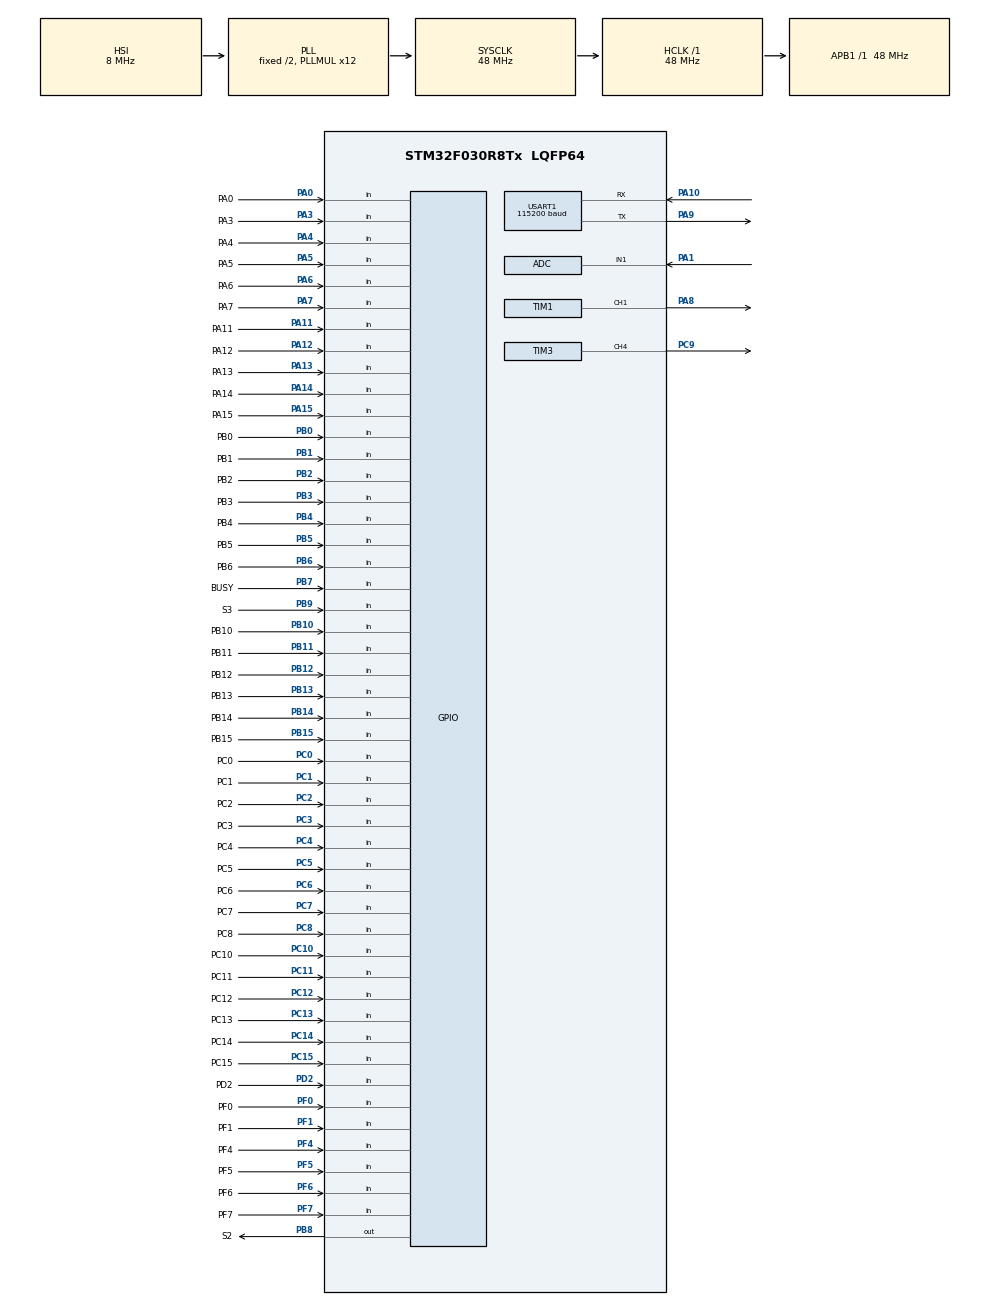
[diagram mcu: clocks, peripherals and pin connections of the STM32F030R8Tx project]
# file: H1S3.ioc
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Mcu.Family=STM32F0
Mcu.Name=STM32F030R8Tx
Mcu.Package=LQFP64
NVIC.USART1_IRQn=true\:0\:0\:false\:false\:true\:true\:true\:true
PA0.GPIO_Label=PA0
PA0.GPIO_PuPd=GPIO_PULLUP
PA0.Signal=GPIO_Input
PA1.Mode=IN1
PA1.Signal=ADC_IN1
PA10.Mode=Asynchronous
PA10.Signal=USART1_RX
PA11.GPIO_Label=PA11
PA11.GPIO_PuPd=GPIO_PULLUP
PA11.Signal=GPIO_Input
PA12.GPIO_Label=PA12
PA12.GPIO_PuPd=GPIO_PULLUP
PA12.Signal=GPIO_Input
PA13.GPIO_Label=PA13
PA13.GPIO_PuPd=GPIO_PULLUP
PA13.Signal=GPIO_Input
PA14.GPIO_Label=PA14
PA14.GPIO_PuPd=GPIO_PULLUP
PA14.Signal=GPIO_Input
PA15.GPIO_Label=PA15
PA15.GPIO_PuPd=GPIO_PULLUP
PA15.Signal=GPIO_Input
PA3.GPIO_Label=PA3
PA3.GPIO_PuPd=GPIO_PULLUP
PA3.Signal=GPIO_Input
PA4.GPIO_Label=PA4
PA4.GPIO_PuPd=GPIO_PULLUP
PA4.Signal=GPIO_Input
PA5.GPIO_Label=PA5
PA5.GPIO_PuPd=GPIO_PULLUP
PA5.Signal=GPIO_Input
PA6.GPIO_Label=PA6
PA6.GPIO_PuPd=GPIO_PULLUP
PA6.Signal=GPIO_Input
PA7.GPIO_Label=PA7
PA7.GPIO_PuPd=GPIO_PULLUP
PA7.Signal=GPIO_Input
PA8.Signal=S_TIM1_CH1
PA9.GPIO_ModeDefaultPP=GPIO_MODE_AF_OD
PA9.GPIO_PuPd=GPIO_PULLUP
PA9.Mode=Asynchronous
PA9.Signal=USART1_TX
PB0.GPIO_Label=PB0
PB0.GPIO_PuPd=GPIO_PULLUP
PB0.Signal=GPIO_Input
PB1.GPIO_Label=PB1
PB1.GPIO_PuPd=GPIO_PULLUP
PB1.Signal=GPIO_Input
PB10.GPIO_Label=PB10
PB10.GPIO_PuPd=GPIO_PULLUP
PB10.Signal=GPIO_Input
PB11.GPIO_Label=PB11
PB11.GPIO_PuPd=GPIO_PULLUP
PB11.Signal=GPIO_Input
PB12.GPIO_Label=PB12
PB12.GPIO_PuPd=GPIO_PULLUP
PB12.Signal=GPIO_Input
PB13.GPIO_Label=PB13
PB13.GPIO_PuPd=GPIO_PULLUP
PB13.Signal=GPIO_Input
PB14.GPIO_Label=PB14
PB14.GPIO_PuPd=GPIO_PULLUP
PB14.Signal=GPIO_Input
PB15.GPIO_Label=PB15
PB15.GPIO_PuPd=GPIO_PULLUP
PB15.Signal=GPIO_Input
PB2.GPIO_Label=PB2
PB2.GPIO_PuPd=GPIO_PULLUP
PB2.Signal=GPIO_Input
PB3.GPIO_Label=PB3
PB3.GPIO_PuPd=GPIO_PULLUP
PB3.Signal=GPIO_Input
PB4.GPIO_Label=PB4
PB4.GPIO_PuPd=GPIO_PULLUP
PB4.Signal=GPIO_Input
PB5.GPIO_Label=PB5
PB5.GPIO_PuPd=GPIO_PULLUP
PB5.Signal=GPIO_Input
PB6.GPIO_Label=PB6
PB6.GPIO_PuPd=GPIO_PULLUP
PB6.Signal=GPIO_Input
PB7.GPIO_Label=BUSY
PB7.GPIO_PuPd=GPIO_PULLUP
PB7.Signal=GPIO_Input
PB8.GPIO_Label=S2
PB8.GPIO_ModeDefaultOutputPP=GPIO_MODE_OUTPUT_PP
PB8.GPIO_PuPd=GPIO_NOPULL
PB8.PinState=GPIO_PIN_SET
PB8.Signal=GPIO_Output
PB9.GPIO_Label=S3
PB9.GPIO_PuPd=GPIO_PULLUP
PB9.Signal=GPIO_Input
PC0.GPIO_Label=PC0
PC0.GPIO_PuPd=GPIO_PULLUP
PC0.Signal=GPIO_Input
PC1.GPIO_Label=PC1
PC1.GPIO_PuPd=GPIO_PULLUP
PC1.Signal=GPIO_Input
PC10.GPIO_Label=PC10
PC10.GPIO_PuPd=GPIO_PULLUP
PC10.Signal=GPIO_Input
PC11.GPIO_Label=PC11
PC11.GPIO_PuPd=GPIO_PULLUP
PC11.Signal=GPIO_Input
PC12.GPIO_Label=PC12
PC12.GPIO_PuPd=GPIO_PULLUP
PC12.Signal=GPIO_Input
PC13.GPIO_Label=PC13
PC13.GPIO_PuPd=GPIO_PULLUP
PC13.Signal=GPIO_Input
PC14-OSC32_IN.GPIO_Label=PC14
PC14-OSC32_IN.GPIO_PuPd=GPIO_PULLUP
PC14-OSC32_IN.Signal=GPIO_Input
PC15-OSC32_OUT.GPIO_Label=PC15
PC15-OSC32_OUT.GPIO_PuPd=GPIO_PULLUP
PC15-OSC32_OUT.Signal=GPIO_Input
PC2.GPIO_Label=PC2
PC2.GPIO_PuPd=GPIO_PULLUP
PC2.Signal=GPIO_Input
PC3.GPIO_Label=PC3
PC3.GPIO_PuPd=GPIO_PULLUP
PC3.Signal=GPIO_Input
PC4.GPIO_Label=PC4
PC4.GPIO_PuPd=GPIO_PULLUP
PC4.Signal=GPIO_Input
PC5.GPIO_Label=PC5
PC5.GPIO_PuPd=GPIO_PULLUP
PC5.Signal=GPIO_Input
PC6.GPIO_Label=PC6
PC6.GPIO_PuPd=GPIO_PULLUP
PC6.Signal=GPIO_Input
PC7.GPIO_Label=PC7
PC7.GPIO_PuPd=GPIO_PULLUP
PC7.Signal=GPIO_Input
PC8.GPIO_Label=PC8
PC8.GPIO_PuPd=GPIO_PULLUP
PC8.Signal=GPIO_Input
PC9.Signal=S_TIM3_CH4
PD2.GPIO_Label=PD2
PD2.GPIO_PuPd=GPIO_PULLUP
PD2.Signal=GPIO_Input
PF0-OSC_IN.GPIO_Label=PF0
PF0-OSC_IN.GPIO_PuPd=GPIO_PULLUP
PF0-OSC_IN.Signal=GPIO_Input
PF1-OSC_OUT.GPIO_Label=PF1
PF1-OSC_OUT.GPIO_PuPd=GPIO_PULLUP
PF1-OSC_OUT.Signal=GPIO_Input
PF4.GPIO_Label=PF4
PF4.GPIO_PuPd=GPIO_PULLUP
PF4.Signal=GPIO_Input
PF5.GPIO_Label=PF5
PF5.GPIO_PuPd=GPIO_PULLUP
PF5.Signal=GPIO_Input
PF6.GPIO_Label=PF6
PF6.GPIO_PuPd=GPIO_PULLUP
PF6.Signal=GPIO_Input
PF7.GPIO_Label=PF7
PF7.GPIO_PuPd=GPIO_PULLUP
PF7.Signal=GPIO_Input
ProjectManager.HeapSize=0x200
ProjectManager.StackSize=0x400
ProjectManager.TargetToolchain=STM32CubeIDE
RCC.AHBFreq_Value=48000000
RCC.APB1Freq_Value=48000000
RCC.APB1TimFreq_Value=48000000
RCC.HCLKFreq_Value=48000000
RCC.PLLMUL=RCC_PLL_MUL12
RCC.SYSCLKFreq_VALUE=48000000
RCC.SYSCLKSource=RCC_SYSCLKSOURCE_PLLCLK
SH.S_TIM1_CH1.0=TIM1_CH1,PWM Generation1 CH1
SH.S_TIM3_CH4.0=TIM3_CH4,PWM Generation4 CH4
TIM1.AutoReloadPreload=TIM_AUTORELOAD_PRELOAD_DISABLE
TIM1.Channel-PWM\ Generation1\ CH1=TIM_CHANNEL_1
TIM1.OC1Preload_PWM=ENABLE
TIM1.Period=2000
TIM1.Pulse-PWM\ Generation1\ CH1=100
TIM1.TIM_MasterOutputTrigger=TIM_TRGO_UPDATE
TIM3.AutoReloadPreload=TIM_AUTORELOAD_PRELOAD_DISABLE
TIM3.Channel-PWM\ Generation4\ CH4=TIM_CHANNEL_4
TIM3.OC4Preload_PWM=ENABLE
TIM3.Period=2000
TIM3.Prescaler=0
TIM3.Pulse-PWM\ Generation4\ CH4=1000
USART1.BaudRate=115200
USART1.VirtualMode-Asynchronous=VM_ASYNC
VP_TIM15_VS_ClockSourceINT.Mode=Internal
VP_TIM1_VS_ClockSourceINT.Mode=Internal
VP_TIM3_VS_ClockSourceINT.Mode=Internal
board=custom

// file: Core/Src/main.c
/* USER CODE BEGIN Header */
/**
  ******************************************************************************
  * @file           : main.c
  * @brief          : Main program body
  ******************************************************************************
  * @attention
  *
  * Copyright (c) 2025 STMicroelectronics.
  * All rights reserved.
  *
  * This software is licensed under terms that can be found in the LICENSE file
  * in the root directory of this software component.
  * If no LICENSE file comes with this software, it is provided AS-IS.
  *
  ******************************************************************************
  */
/* USER CODE END Header */
#include "main.h"

/* USER CODE BEGIN Includes */
#include "matrix.cs"
/* USER CODE END Includes */

ADC_HandleTypeDef hadc;

TIM_HandleTypeDef htim1;
TIM_HandleTypeDef htim3;
TIM_HandleTypeDef htim15;

UART_HandleTypeDef huart1;

void SystemClock_Config(void);
static void MX_GPIO_Init(void);
static void MX_USART1_UART_Init(void);
static void MX_ADC_Init(void);
static void MX_TIM3_Init(void);
static void MX_TIM1_Init(void);
static void MX_TIM15_Init(void);

/* USER CODE BEGIN 0 */
char UART1_Read(void) {
	char myChar[1] = " ";
	HAL_UART_Receive(&huart1, myChar, 1, 100);
	return myChar[0];
}
/* USER CODE END 0 */

int main(void)
{

  /* MCU Configuration--------------------------------------------------------*/

  /* Reset of all peripherals, Initializes the Flash interface and the Systick. */
  HAL_Init();

  /* Configure the system clock */
  SystemClock_Config();

  /* Initialize all configured peripherals */
  MX_GPIO_Init();
  MX_USART1_UART_Init();
  MX_ADC_Init();
  MX_TIM3_Init();
  MX_TIM1_Init();
  MX_TIM15_Init();
  /* USER CODE BEGIN 2 */
	__HAL_UART_ENABLE_IT(&huart1, UART_IT_RXNE);
	HAL_TIM_PWM_Start(&htim3, TIM_CHANNEL_4);
	HAL_TIM_PWM_Start(&htim1, TIM_CHANNEL_1);
	MainInit();
  /* USER CODE END 2 */

  /* Infinite loop */
  while (1)
  {

    /* USER CODE BEGIN 3 */
	  MainLoop();
  }
  /* USER CODE END 3 */
}

void SystemClock_Config(void)
{
  RCC_OscInitTypeDef RCC_OscInitStruct = {0};
  RCC_ClkInitTypeDef RCC_ClkInitStruct = {0};
  RCC_PeriphCLKInitTypeDef PeriphClkInit = {0};

  /** Initializes the RCC Oscillators according to the specified parameters
  * in the RCC_OscInitTypeDef structure.
  */
  RCC_OscInitStruct.OscillatorType = RCC_OSCILLATORTYPE_HSI|RCC_OSCILLATORTYPE_HSI14;
  RCC_OscInitStruct.HSIState = RCC_HSI_ON;
  RCC_OscInitStruct.HSI14State = RCC_HSI14_ON;
  RCC_OscInitStruct.HSICalibrationValue = RCC_HSICALIBRATION_DEFAULT;
  RCC_OscInitStruct.HSI14CalibrationValue = 16;
  RCC_OscInitStruct.PLL.PLLState = RCC_PLL_ON;
  RCC_OscInitStruct.PLL.PLLSource = RCC_PLLSOURCE_HSI;
  RCC_OscInitStruct.PLL.PLLMUL = RCC_PLL_MUL12;
  RCC_OscInitStruct.PLL.PREDIV = RCC_PREDIV_DIV1;
  if (HAL_RCC_OscConfig(&RCC_OscInitStruct) != HAL_OK)
  {
    Error_Handler();
  }

  /** Initializes the CPU, AHB and APB buses clocks
  */
  RCC_ClkInitStruct.ClockType = RCC_CLOCKTYPE_HCLK|RCC_CLOCKTYPE_SYSCLK
                              |RCC_CLOCKTYPE_PCLK1;
  RCC_ClkInitStruct.SYSCLKSource = RCC_SYSCLKSOURCE_PLLCLK;
  RCC_ClkInitStruct.AHBCLKDivider = RCC_SYSCLK_DIV1;
  RCC_ClkInitStruct.APB1CLKDivider = RCC_HCLK_DIV1;

  if (HAL_RCC_ClockConfig(&RCC_ClkInitStruct, FLASH_LATENCY_1) != HAL_OK)
  {
    Error_Handler();
  }
  PeriphClkInit.PeriphClockSelection = RCC_PERIPHCLK_USART1;
  PeriphClkInit.Usart1ClockSelection = RCC_USART1CLKSOURCE_PCLK1;
  if (HAL_RCCEx_PeriphCLKConfig(&PeriphClkInit) != HAL_OK)
  {
    Error_Handler();
  }
}

static void MX_ADC_Init(void)
{

  ADC_ChannelConfTypeDef sConfig = {0};

  /** Configure the global features of the ADC (Clock, Resolution, Data Alignment and number of conversion)
  */
  hadc.Instance = ADC1;
  hadc.Init.ClockPrescaler = ADC_CLOCK_ASYNC_DIV1;
  hadc.Init.Resolution = ADC_RESOLUTION_12B;
  hadc.Init.DataAlign = ADC_DATAALIGN_RIGHT;
  hadc.Init.ScanConvMode = ADC_SCAN_DIRECTION_FORWARD;
  hadc.Init.EOCSelection = ADC_EOC_SINGLE_CONV;
  hadc.Init.LowPowerAutoWait = DISABLE;
  hadc.Init.LowPowerAutoPowerOff = DISABLE;
  hadc.Init.ContinuousConvMode = DISABLE;
  hadc.Init.DiscontinuousConvMode = DISABLE;
  hadc.Init.ExternalTrigConv = ADC_SOFTWARE_START;
  hadc.Init.ExternalTrigConvEdge = ADC_EXTERNALTRIGCONVEDGE_NONE;
  hadc.Init.DMAContinuousRequests = DISABLE;
  hadc.Init.Overrun = ADC_OVR_DATA_PRESERVED;
  if (HAL_ADC_Init(&hadc) != HAL_OK)
  {
    Error_Handler();
  }

  /** Configure for the selected ADC regular channel to be converted.
  */
  sConfig.Channel = ADC_CHANNEL_1;
  sConfig.Rank = ADC_RANK_CHANNEL_NUMBER;
  sConfig.SamplingTime = ADC_SAMPLETIME_1CYCLE_5;
  if (HAL_ADC_ConfigChannel(&hadc, &sConfig) != HAL_OK)
  {
    Error_Handler();
  }

}

static void MX_TIM1_Init(void)
{

  TIM_ClockConfigTypeDef sClockSourceConfig = {0};
  TIM_MasterConfigTypeDef sMasterConfig = {0};
  TIM_OC_InitTypeDef sConfigOC = {0};
  TIM_BreakDeadTimeConfigTypeDef sBreakDeadTimeConfig = {0};

  htim1.Instance = TIM1;
  htim1.Init.Prescaler = 0;
  htim1.Init.CounterMode = TIM_COUNTERMODE_UP;
  htim1.Init.Period = 2000;
  htim1.Init.ClockDivision = TIM_CLOCKDIVISION_DIV1;
  htim1.Init.RepetitionCounter = 0;
  htim1.Init.AutoReloadPreload = TIM_AUTORELOAD_PRELOAD_DISABLE;
  if (HAL_TIM_Base_Init(&htim1) != HAL_OK)
  {
    Error_Handler();
  }
  sClockSourceConfig.ClockSource = TIM_CLOCKSOURCE_INTERNAL;
  if (HAL_TIM_ConfigClockSource(&htim1, &sClockSourceConfig) != HAL_OK)
  {
    Error_Handler();
  }
  if (HAL_TIM_PWM_Init(&htim1) != HAL_OK)
  {
    Error_Handler();
  }
  sMasterConfig.MasterOutputTrigger = TIM_TRGO_UPDATE;
  sMasterConfig.MasterSlaveMode = TIM_MASTERSLAVEMODE_DISABLE;
  if (HAL_TIMEx_MasterConfigSynchronization(&htim1, &sMasterConfig) != HAL_OK)
  {
    Error_Handler();
  }
  sConfigOC.OCMode = TIM_OCMODE_PWM1;
  sConfigOC.Pulse = 100;
  sConfigOC.OCPolarity = TIM_OCPOLARITY_HIGH;
  sConfigOC.OCNPolarity = TIM_OCNPOLARITY_HIGH;
  sConfigOC.OCFastMode = TIM_OCFAST_DISABLE;
  sConfigOC.OCIdleState = TIM_OCIDLESTATE_RESET;
  sConfigOC.OCNIdleState = TIM_OCNIDLESTATE_RESET;
  if (HAL_TIM_PWM_ConfigChannel(&htim1, &sConfigOC, TIM_CHANNEL_1) != HAL_OK)
  {
    Error_Handler();
  }
  sBreakDeadTimeConfig.OffStateRunMode = TIM_OSSR_DISABLE;
  sBreakDeadTimeConfig.OffStateIDLEMode = TIM_OSSI_DISABLE;
  sBreakDeadTimeConfig.LockLevel = TIM_LOCKLEVEL_OFF;
  sBreakDeadTimeConfig.DeadTime = 0;
  sBreakDeadTimeConfig.BreakState = TIM_BREAK_DISABLE;
  sBreakDeadTimeConfig.BreakPolarity = TIM_BREAKPOLARITY_HIGH;
  sBreakDeadTimeConfig.AutomaticOutput = TIM_AUTOMATICOUTPUT_DISABLE;
  if (HAL_TIMEx_ConfigBreakDeadTime(&htim1, &sBreakDeadTimeConfig) != HAL_OK)
  {
    Error_Handler();
  }
  HAL_TIM_MspPostInit(&htim1);

}

static void MX_TIM3_Init(void)
{

  TIM_ClockConfigTypeDef sClockSourceConfig = {0};
  TIM_MasterConfigTypeDef sMasterConfig = {0};
  TIM_OC_InitTypeDef sConfigOC = {0};

  htim3.Instance = TIM3;
  htim3.Init.Prescaler = 0;
  htim3.Init.CounterMode = TIM_COUNTERMODE_UP;
  htim3.Init.Period = 2000;
  htim3.Init.ClockDivision = TIM_CLOCKDIVISION_DIV1;
  htim3.Init.AutoReloadPreload = TIM_AUTORELOAD_PRELOAD_DISABLE;
  if (HAL_TIM_Base_Init(&htim3) != HAL_OK)
  {
    Error_Handler();
  }
  sClockSourceConfig.ClockSource = TIM_CLOCKSOURCE_INTERNAL;
  if (HAL_TIM_ConfigClockSource(&htim3, &sClockSourceConfig) != HAL_OK)
  {
    Error_Handler();
  }
  if (HAL_TIM_PWM_Init(&htim3) != HAL_OK)
  {
    Error_Handler();
  }
  sMasterConfig.MasterOutputTrigger = TIM_TRGO_RESET;
  sMasterConfig.MasterSlaveMode = TIM_MASTERSLAVEMODE_DISABLE;
  if (HAL_TIMEx_MasterConfigSynchronization(&htim3, &sMasterConfig) != HAL_OK)
  {
    Error_Handler();
  }
  sConfigOC.OCMode = TIM_OCMODE_PWM1;
  sConfigOC.Pulse = 1000;
  sConfigOC.OCPolarity = TIM_OCPOLARITY_HIGH;
  sConfigOC.OCFastMode = TIM_OCFAST_DISABLE;
  if (HAL_TIM_PWM_ConfigChannel(&htim3, &sConfigOC, TIM_CHANNEL_4) != HAL_OK)
  {
    Error_Handler();
  }
  HAL_TIM_MspPostInit(&htim3);

}

static void MX_TIM15_Init(void)
{

  TIM_ClockConfigTypeDef sClockSourceConfig = {0};
  TIM_MasterConfigTypeDef sMasterConfig = {0};

  htim15.Instance = TIM15;
  htim15.Init.Prescaler = 0;
  htim15.Init.CounterMode = TIM_COUNTERMODE_UP;
  htim15.Init.Period = 65535;
  htim15.Init.ClockDivision = TIM_CLOCKDIVISION_DIV1;
  htim15.Init.RepetitionCounter = 0;
  htim15.Init.AutoReloadPreload = TIM_AUTORELOAD_PRELOAD_DISABLE;
  if (HAL_TIM_Base_Init(&htim15) != HAL_OK)
  {
    Error_Handler();
  }
  sClockSourceConfig.ClockSource = TIM_CLOCKSOURCE_INTERNAL;
  if (HAL_TIM_ConfigClockSource(&htim15, &sClockSourceConfig) != HAL_OK)
  {
    Error_Handler();
  }
  sMasterConfig.MasterOutputTrigger = TIM_TRGO_RESET;
  sMasterConfig.MasterSlaveMode = TIM_MASTERSLAVEMODE_DISABLE;
  if (HAL_TIMEx_MasterConfigSynchronization(&htim15, &sMasterConfig) != HAL_OK)
  {
    Error_Handler();
  }

}

static void MX_USART1_UART_Init(void)
{

  huart1.Instance = USART1;
  huart1.Init.BaudRate = 115200;
  huart1.Init.WordLength = UART_WORDLENGTH_8B;
  huart1.Init.StopBits = UART_STOPBITS_1;
  huart1.Init.Parity = UART_PARITY_NONE;
  huart1.Init.Mode = UART_MODE_TX_RX;
  huart1.Init.HwFlowCtl = UART_HWCONTROL_NONE;
  huart1.Init.OverSampling = UART_OVERSAMPLING_16;
  huart1.Init.OneBitSampling = UART_ONE_BIT_SAMPLE_DISABLE;
  huart1.AdvancedInit.AdvFeatureInit = UART_ADVFEATURE_NO_INIT;
  if (HAL_UART_Init(&huart1) != HAL_OK)
  {
    Error_Handler();
  }

}

static void MX_GPIO_Init(void)
{
  GPIO_InitTypeDef GPIO_InitStruct = {0};

  /* GPIO Ports Clock Enable */
  __HAL_RCC_GPIOC_CLK_ENABLE();
  __HAL_RCC_GPIOF_CLK_ENABLE();
  __HAL_RCC_GPIOA_CLK_ENABLE();
  __HAL_RCC_GPIOB_CLK_ENABLE();
  __HAL_RCC_GPIOD_CLK_ENABLE();

  /*Configure GPIO pin Output Level */
  HAL_GPIO_WritePin(S2_GPIO_Port, S2_Pin, GPIO_PIN_SET);

  /*Configure GPIO pins : PC13_Pin PC14_Pin PC15_Pin PC0_Pin
                           PC1_Pin PC2_Pin PC3_Pin PC4_Pin
                           PC5_Pin PC6_Pin PC7_Pin PC8_Pin
                           PC10_Pin PC11_Pin PC12_Pin */
  GPIO_InitStruct.Pin = PC13_Pin|PC14_Pin|PC15_Pin|PC0_Pin
                          |PC1_Pin|PC2_Pin|PC3_Pin|PC4_Pin
                          |PC5_Pin|PC6_Pin|PC7_Pin|PC8_Pin
                          |PC10_Pin|PC11_Pin|PC12_Pin;
  GPIO_InitStruct.Mode = GPIO_MODE_INPUT;
  GPIO_InitStruct.Pull = GPIO_PULLUP;
  HAL_GPIO_Init(GPIOC, &GPIO_InitStruct);

  /*Configure GPIO pins : PF0_Pin PF1_Pin PF4_Pin PF5_Pin
                           PF6_Pin PF7_Pin */
  GPIO_InitStruct.Pin = PF0_Pin|PF1_Pin|PF4_Pin|PF5_Pin
                          |PF6_Pin|PF7_Pin;
  GPIO_InitStruct.Mode = GPIO_MODE_INPUT;
  GPIO_InitStruct.Pull = GPIO_PULLUP;
  HAL_GPIO_Init(GPIOF, &GPIO_InitStruct);

  /*Configure GPIO pins : PA0_Pin PA3_Pin PA4_Pin PA5_Pin
                           PA6_Pin PA7_Pin PA11_Pin PA12_Pin
                           PA13_Pin PA14_Pin PA15_Pin */
  GPIO_InitStruct.Pin = PA0_Pin|PA3_Pin|PA4_Pin|PA5_Pin
                          |PA6_Pin|PA7_Pin|PA11_Pin|PA12_Pin
                          |PA13_Pin|PA14_Pin|PA15_Pin;
  GPIO_InitStruct.Mode = GPIO_MODE_INPUT;
  GPIO_InitStruct.Pull = GPIO_PULLUP;
  HAL_GPIO_Init(GPIOA, &GPIO_InitStruct);

  /*Configure GPIO pins : PB0_Pin PB1_Pin PB2_Pin PB10_Pin
                           PB11_Pin PB12_Pin PB13_Pin PB14_Pin
                           PB15_Pin PB3_Pin PB4_Pin PB5_Pin
                           PB6_Pin BUSY_Pin S3_Pin */
  GPIO_InitStruct.Pin = PB0_Pin|PB1_Pin|PB2_Pin|PB10_Pin
                          |PB11_Pin|PB12_Pin|PB13_Pin|PB14_Pin
                          |PB15_Pin|PB3_Pin|PB4_Pin|PB5_Pin
                          |PB6_Pin|BUSY_Pin|S3_Pin;
  GPIO_InitStruct.Mode = GPIO_MODE_INPUT;
  GPIO_InitStruct.Pull = GPIO_PULLUP;
  HAL_GPIO_Init(GPIOB, &GPIO_InitStruct);

  /*Configure GPIO pin : PD2_Pin */
  GPIO_InitStruct.Pin = PD2_Pin;
  GPIO_InitStruct.Mode = GPIO_MODE_INPUT;
  GPIO_InitStruct.Pull = GPIO_PULLUP;
  HAL_GPIO_Init(PD2_GPIO_Port, &GPIO_InitStruct);

  /*Configure GPIO pin : S2_Pin */
  GPIO_InitStruct.Pin = S2_Pin;
  GPIO_InitStruct.Mode = GPIO_MODE_OUTPUT_PP;
  GPIO_InitStruct.Pull = GPIO_NOPULL;
  GPIO_InitStruct.Speed = GPIO_SPEED_FREQ_LOW;
  HAL_GPIO_Init(S2_GPIO_Port, &GPIO_InitStruct);

}

void Error_Handler(void)
{
  __disable_irq();
  while (1)
  {
  }
}
